# G32R501 register map
Vendor: Geehy Semiconductor Co., Ltd.; Series: G32R5; File version: 1.0
CPU: CM55 r0p1, little endian, MPU, FPU, double-precision FPU, DSP, VTOR, 4 interrupt priority bits
Registers are 32-bit, read-write, reset 0x0 unless marked. A register's access mark holds for its fields unless they carry their own. Offsets are from the block's base; [hi:lo] are bit positions; {n}, {i} and the like mark numbered series.

## LIN
Base 0x50000000
0x00 LINGCTRL0 — Global Control Register 0
  [0] RST — USART/LIN reset
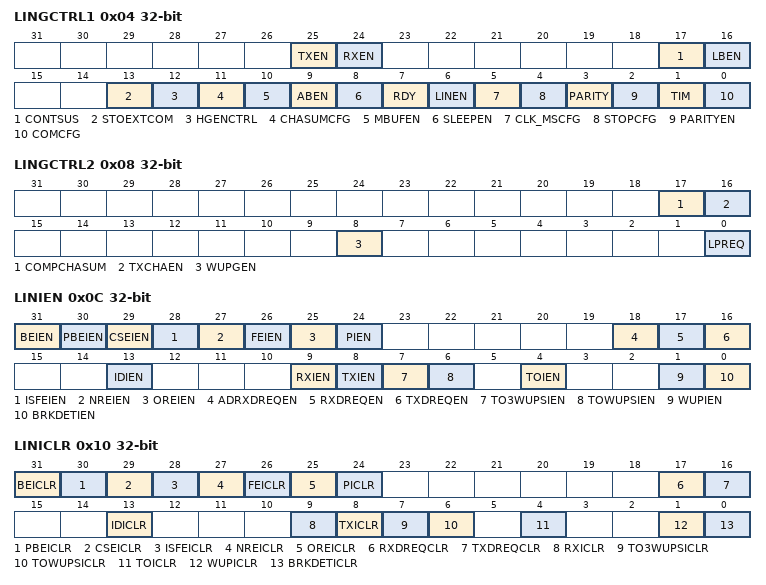
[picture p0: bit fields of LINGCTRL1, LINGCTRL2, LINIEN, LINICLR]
0x04 LINGCTRL1 — Global Control Register 1
  [25] TXEN — USART/LIN Transmit enable
  [24] RXEN — USART/LIN Receive enable
  [17] CONTSUS — USART/LIN Continue work on suspend
  [16] LBEN — USART/LIN Loopback Mode Enable
  [13] STOEXTCOM — Stop LIN extended frame communication
  [12] HGENCTRL — LIN HGEN control
  [11] CHASUMCFG — LIN Checksum Configure
  [10] MBUFEN — USART/LIN multi-buffer mode enable
  [9] ABEN — LIN Automatic baudrate adjustment enable
  [8] SLEEPEN — USART Sleep mode enable
  [7] RDY — USART/LIN Ready
  [6] LINEN — LIN mode Enable
  [5] CLK_MSCFG — USART internal clock enable/LIN Master Slave configure
  [4] STOPCFG — USART STOP Bit Configure
  [3] PARITY — USART Odd/Even Parity Select
  [2] PARITYEN — USART/LIN Parity Enable
  [1] TIM — USART timing mode
  [0] COMCFG — USART/LIN communication mode Configure
0x08 LINGCTRL2 — Global Control Register 2
  [17] COMPCHASUM — Compare Checksum
  [16] TXCHAEN — Transmit Checksum Byte Enable
  [8] WUPGEN — Generate wakeup signal
  [0] LPREQ — low-power mode Request
0x0C LINIEN — Interrupt Enable Register
  [31] BEIEN — bit error interrupt Enable
  [30] PBEIEN — physical bus error interrupt Enable
  [29] CSEIEN — checksum-error Interrupt Enable
  [28] ISFEIEN — inconsistent sync field error interrupt Enable
  [27] NREIEN — no response error interrupt Enable
  [26] FEIEN — framing error interrupt Enable
  [25] OREIEN — overrun error interrupt Enable
  [24] PIEN — parity interrupt Enable
  [18] ADRXDREQEN — Address & Data frames Receive DMA request enable
  [17] RXDREQEN — Receive DMA request enable
  [16] TXDREQEN — transmit DMA request enable
  [13] IDIEN — Identification interrupt Enable
  [9] RXIEN — Receiver interrupt Enable
  [8] TXIEN — Transmitter interrupt Enable
  [7] TO3WUPSIEN — Timeout After 3 Wakeup Signal interrupt Enable
  [6] TOWUPSIEN — Timeout After Wakeup Signal interrupt Enable
  [4] TOIEN — timeout interrupt Enable
  [1] WUPIEN — wake up interrupt Enable
  [0] BRKDETIEN — break detect interrupt Enable
0x10 LINICLR — Interrupt Disable Register
  [31] BEICLR — bit error interrupt Clear
  [30] PBEICLR — physical bus error interrupt Clear
  [29] CSEICLR — checksum-error Interrupt Clear
  [28] ISFEICLR — inconsistent sync field error interrupt Clear
  [27] NREICLR — no response error interrupt Clear
  [26] FEICLR — framing error interrupt Clear
  [25] OREICLR — overrun error interrupt Clear
  [24] PICLR — parity interrupt Clear
  [17] RXDREQCLR — Receive DMA request Clear
  [16] TXDREQCLR — transmit DMA request Clear
  [13] IDICLR — Identification interrupt Clear
  [9] RXICLR — Receiver interrupt Clear
  [8] TXICLR — Transmitter interrupt Clear
  [7] TO3WUPSICLR — Timeout After 3 Wakeup Signal interrupt Clear
  [6] TOWUPSICLR — Timeout After Wakeup Signal interrupt Clear
  [4] TOICLR — timeout interrupt Clear
  [1] WUPICLR — wake up interrupt Clear
  [0] BRKDETICLR — break detect interrupt Clear
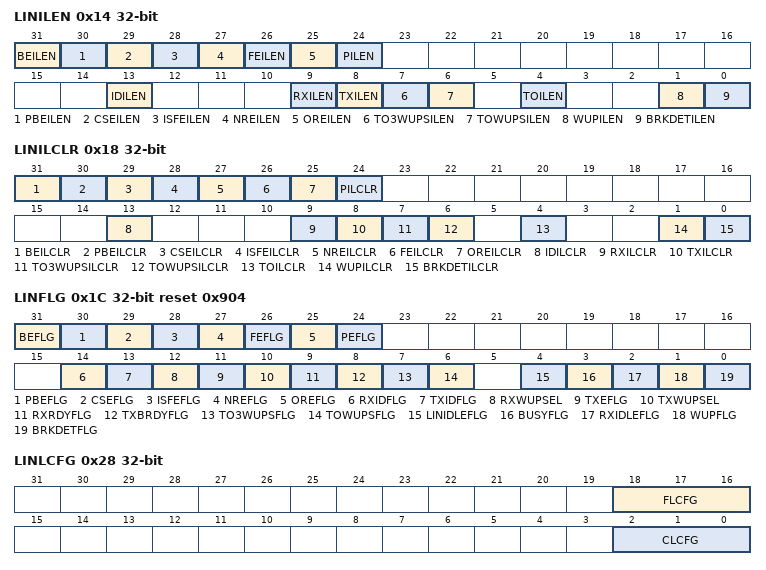
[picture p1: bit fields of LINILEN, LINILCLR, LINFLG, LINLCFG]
0x14 LINILEN — Set Interrupt Level Register
  [31] BEILEN — bit error interrupt level 1 Enable
  [30] PBEILEN — physical bus error interrupt level 1 Enable
  [29] CSEILEN — checksum-error Interrupt level 1 Enable
  [28] ISFEILEN — inconsistent sync field error interrupt level 1 Enable
  [27] NREILEN — no response error interrupt level 1 Enable
  [26] FEILEN — framing error interrupt level 1 Enable
  [25] OREILEN — overrun error interrupt level 1 Enable
  [24] PILEN — parity interrupt level 1 Enable
  [13] IDILEN — Identification interrupt level 1 Enable
  [9] RXILEN — Receiver interrupt level 1 Enable
  [8] TXILEN — Transmitter interrupt level 1 Enable
  [7] TO3WUPSILEN — Timeout After 3 Wakeup Signal interrupt level 1 Enable
  [6] TOWUPSILEN — Timeout After Wakeup Signal interrupt level 1 Enable
  [4] TOILEN — timeout interrupt level 1 Enable
  [1] WUPILEN — wake up interrupt level 1 Enable
  [0] BRKDETILEN — break detect interrupt level 1 Enable
0x18 LINILCLR — Clear Interrupt Level Register
  [31] BEILCLR — bit error interrupt level 1 Clear
  [30] PBEILCLR — physical bus error interrupt level 1 Clear
  [29] CSEILCLR — checksum-error Interrupt level 1 Clear
  [28] ISFEILCLR — inconsistent sync field error interrupt level 1 Clear
  [27] NREILCLR — no response error interrupt level 1 Clear
  [26] FEILCLR — framing error interrupt level 1 Clear
  [25] OREILCLR — overrun error interrupt level 1 Clear
  [24] PILCLR — parity interrupt level 1 Clear
  [13] IDILCLR — Identification interrupt level 1 Clear
  [9] RXILCLR — Receiver interrupt level 1 Clear
  [8] TXILCLR — Transmitter interrupt level 1 Clear
  [7] TO3WUPSILCLR — Timeout After 3 Wakeup Signal interrupt level 1 Clear
  [6] TOWUPSILCLR — Timeout After Wakeup Signal interrupt level 1 Clear
  [4] TOILCLR — timeout interrupt level 1 Clear
  [1] WUPILCLR — wake up interrupt level 1 Clear
  [0] BRKDETILCLR — break detect interrupt level 1 Clear
0x1C LINFLG access per field reset 0x904 — Flag Register
  [31] BEFLG rw — Bit Error Flag
  [30] PBEFLG rw — Physical Bus Error Flag
  [29] CSEFLG rw — Checksum Error Flag
  [28] ISFEFLG rw — Inconsistent Sync Field Error Flag
  [27] NREFLG rw — No Response Error Flag
  [26] FEFLG rw — Framing error flag
  [25] OREFLG rw — Overrun error flag
  [24] PEFLG rw — Parity error flag
  [14] RXIDFLG rw — Receive Identifier Flag
  [13] TXIDFLG rw — Transmit Identifier Flag
  [12] RXWUPSEL ro — Receiver wakeup mode select
  [11] TXEFLG ro — Transmitter Empty flag
  [10] TXWUPSEL rw — Transmitter wakeup mode select
  [9] RXRDYFLG rw — Receiver ready flag
  [8] TXBRDYFLG ro — Transmitter buffer ready flag
  [7] TO3WUPSFLG rw — Timeout After 3 Wakeup Signal flag
  [6] TOWUPSFLG rw — Timeout After Wakeup Signal flag
  [4] LINIDLEFLG rw — LIN bus idle flag
  [3] BUSYFLG ro — Bus BUSY flag
  [2] RXIDLEFLG ro — receiver idle flag
  [1] WUPFLG rw — Wake up flag
  [0] BRKDETFLG rw — Break detect flag
0x20 LINIVO0 ro — Interrupt Vector Offset Register 0
  [4:0] IVO0 — INT0 Interrupt vector offset
0x24 LINIVO1 ro — Interrupt Vector Offset Register 1
  [4:0] IVO1 — INT1 Interrupt vector offset
0x28 LINLCFG — Length Control Register
  [18:16] FLCFG — Frame length Configure
  [2:0] CLCFG — Character length Configure
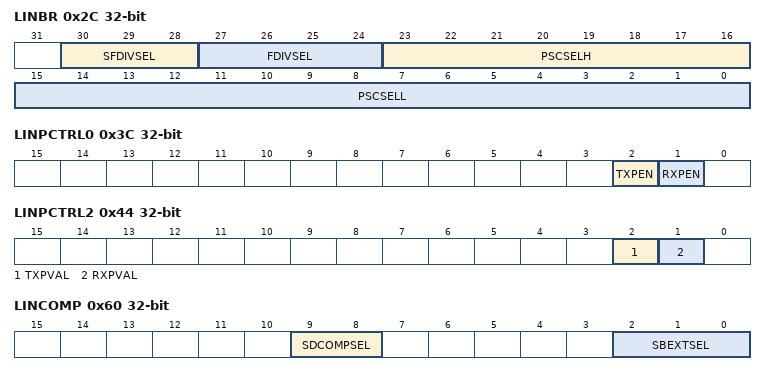
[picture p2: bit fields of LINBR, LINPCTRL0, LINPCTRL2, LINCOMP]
0x2C LINBR — Baud Rate Selection Register
  [30:28] SFDIVSEL — Superfractional Divider Selcet
  [27:24] FDIVSEL — 4 bit Fractional Divider Selcet
  [23:16] PSCSELH — Prescaler Selcet
  [15:0] PSCSELL — Prescaler Selcet
0x30 LINRXED ro — Emulation buffer Register
  [7:0] RXED — Receiver Emulation Data
0x34 LINRXD ro — Receiver data buffer Register
  [7:0] RXD — Received Data
0x38 LINTXD — Transmit data buffer Register
  [7:0] TXD — Transmit Data
0x3C LINPCTRL0 — Pin control Register 0
  [2] TXPEN — Transmit pin Enable
  [1] RXPEN — Receive pin Enable
0x44 LINPCTRL2 ro — Pin control Register 2
  [2] TXPVAL — Transmit pin current value
  [1] RXPVAL — Receive pin current value
0x60 LINCOMP — Compare register
  [9:8] SDCOMPSEL — Sync Delimiter compare Selcet
  [2:0] SBEXTSEL — Sync Break extend Selcet
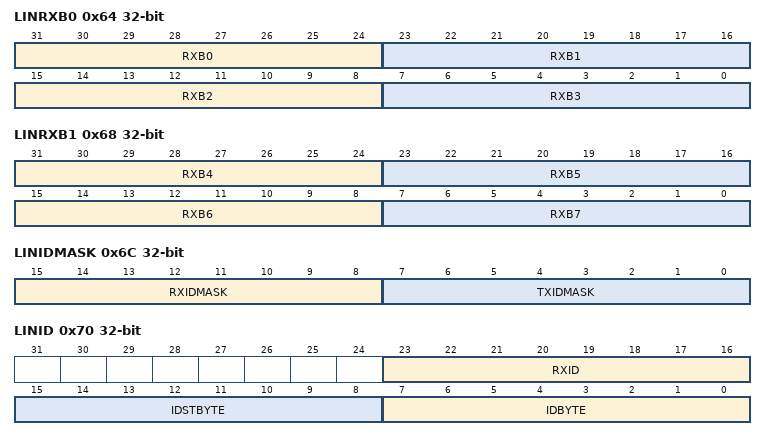
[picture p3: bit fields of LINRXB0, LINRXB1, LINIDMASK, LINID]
0x64 LINRXB0 ro — Receive data register 0
  [31-8n:24-8n] RXB{n} (n=0..3) — Receive Buffer {n}
0x68 LINRXB1 ro — Receive data register 1
  [63-8n:56-8n] RXB{n} (n=4..7) — Receive Buffer {n}
0x6C LINIDMASK — Acceptance mask register
  [15:8] RXIDMASK — Receive ID mask
  [7:0] TXIDMASK — Transmit ID mask
0x70 LINID access per field
  [23:16] RXID ro — Received ID
  [15:8] IDSTBYTE rw — ID Slave Task byte
  [7:0] IDBYTE rw — ID byte Set
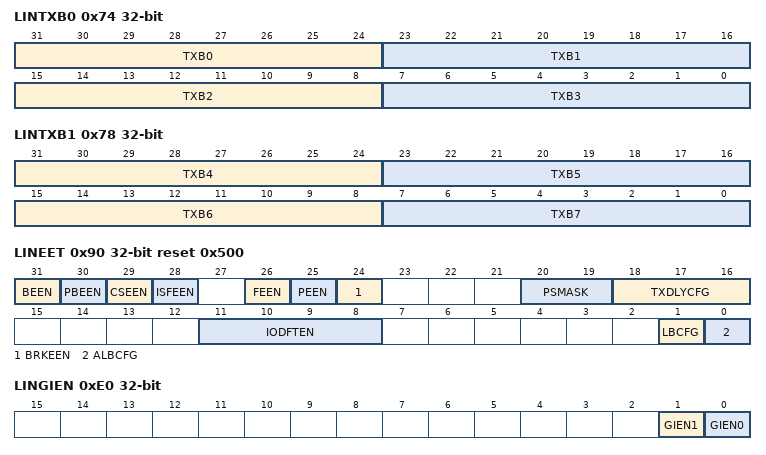
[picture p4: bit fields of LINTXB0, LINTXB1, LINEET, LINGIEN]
0x74 LINTXB0 — Transmit Data Register 0
  [31:24] TXB0 — Receive Buffer 0
  [23:16] TXB1 — Transmit Buffer 1
  [15:8] TXB2 — Transmit Buffer 2
  [7:0] TXB3 — Transmit Buffer 3
0x78 LINTXB1 — Transmit Data Register 1
  [63-8n:56-8n] TXB{n} (n=4..7) — Transmit Buffer {n}
0x7C LINMBRPSC reset 0xDAC — Maximum Baud Rate Selection Register
  [23:16] MBRPSC — Maximum Baud Rate Prescaler
0x90 LINEET reset 0x500 — IODFT for LIN
  [31] BEEN — Bit Error Enable
  [30] PBEEN — Physical Bus Error Enable
  [29] CSEEN — Checksum Error Enable
  [28] ISFEEN — Inconsistent Sync Field Error Enable
  [26] FEEN — Frame error Enable
  [25] PEEN — Parity error Enable
  [24] BRKEEN — BRKDT error Enable
  [20:19] PSMASK — Pin sample mask
  [18:16] TXDLYCFG — Transmit Delay Configure
  [11:8] IODFTEN — IO DFT Enable
  [1] LBCFG — loopback Mode Configure
  [0] ALBCFG — Analog loopback Configure
0xE0 LINGIEN — LIN Global Interrupt Enable Register
  [1] GIEN1 — Global Interrupt Enable for LIN INT1
  [0] GIEN0 — Global Interrupt Enable for LIN INT0
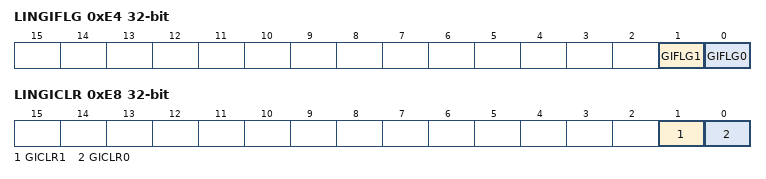
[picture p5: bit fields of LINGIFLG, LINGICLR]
0xE4 LINGIFLG ro — LIN Global Interrupt Flag Register
  [1] GIFLG1 — Global Interrupt Flag for LIN INT1
  [0] GIFLG0 — Global Interrupt Flag for LIN INT0
0xE8 LINGICLR — LIN Global Interrupt Clear Register
  [1] GICLR1 — Global Interrupt Flag clear for LIN INT1
  [0] GICLR0 — Global Interrupt Flag clear for LIN INT0
